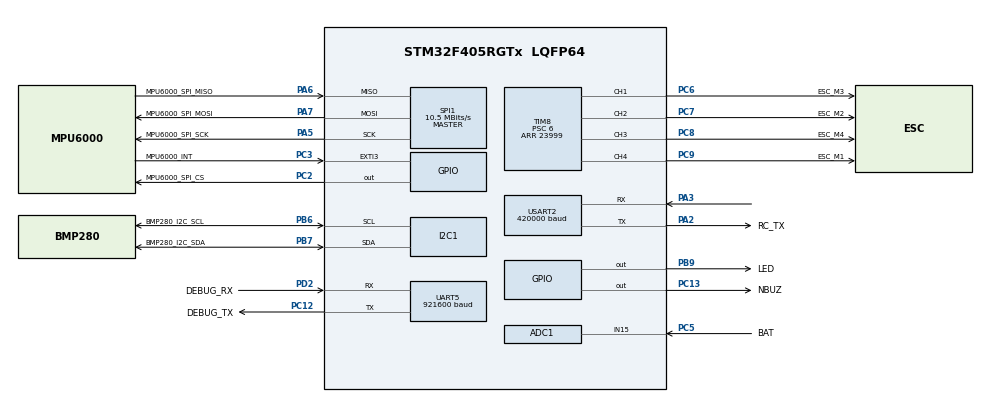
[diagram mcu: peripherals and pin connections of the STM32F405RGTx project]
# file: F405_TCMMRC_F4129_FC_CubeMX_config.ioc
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ADC1.Channel-0\#ChannelRegularConversion=ADC_CHANNEL_15
ADC1.NbrOfConversionFlag=1
ADC1.Rank-0\#ChannelRegularConversion=1
ADC1.SamplingTime-0\#ChannelRegularConversion=ADC_SAMPLETIME_3CYCLES
ADC1.master=1
Dma.Request0=SPI1_RX
Dma.Request1=SPI1_TX
Dma.Request2=USART2_RX
Dma.SPI1_RX.0.Direction=DMA_PERIPH_TO_MEMORY
Dma.SPI1_RX.0.FIFOMode=DMA_FIFOMODE_DISABLE
Dma.SPI1_RX.0.Instance=DMA2_Stream0
Dma.SPI1_RX.0.MemDataAlignment=DMA_MDATAALIGN_BYTE
Dma.SPI1_RX.0.MemInc=DMA_MINC_ENABLE
Dma.SPI1_RX.0.Mode=DMA_NORMAL
Dma.SPI1_RX.0.PeriphDataAlignment=DMA_PDATAALIGN_BYTE
Dma.SPI1_RX.0.PeriphInc=DMA_PINC_DISABLE
Dma.SPI1_RX.0.Priority=DMA_PRIORITY_VERY_HIGH
Dma.SPI1_TX.1.Direction=DMA_MEMORY_TO_PERIPH
Dma.SPI1_TX.1.FIFOMode=DMA_FIFOMODE_DISABLE
Dma.SPI1_TX.1.Instance=DMA2_Stream3
Dma.SPI1_TX.1.MemDataAlignment=DMA_MDATAALIGN_BYTE
Dma.SPI1_TX.1.MemInc=DMA_MINC_ENABLE
Dma.SPI1_TX.1.Mode=DMA_NORMAL
Dma.SPI1_TX.1.PeriphDataAlignment=DMA_PDATAALIGN_BYTE
Dma.SPI1_TX.1.PeriphInc=DMA_PINC_DISABLE
Dma.SPI1_TX.1.Priority=DMA_PRIORITY_VERY_HIGH
Dma.USART2_RX.2.Direction=DMA_PERIPH_TO_MEMORY
Dma.USART2_RX.2.FIFOMode=DMA_FIFOMODE_DISABLE
Dma.USART2_RX.2.Instance=DMA1_Stream5
Dma.USART2_RX.2.MemDataAlignment=DMA_MDATAALIGN_BYTE
Dma.USART2_RX.2.MemInc=DMA_MINC_ENABLE
Dma.USART2_RX.2.Mode=DMA_CIRCULAR
Dma.USART2_RX.2.PeriphDataAlignment=DMA_PDATAALIGN_BYTE
Dma.USART2_RX.2.PeriphInc=DMA_PINC_DISABLE
Dma.USART2_RX.2.Priority=DMA_PRIORITY_HIGH
Mcu.Family=STM32F4
Mcu.Name=STM32F405RGTx
Mcu.Package=LQFP64
NVIC.DMA1_Stream5_IRQn=true\:0\:0\:false\:false\:true\:false\:true\:true
NVIC.DMA2_Stream0_IRQn=true\:2\:0\:true\:false\:true\:false\:true\:true
NVIC.DMA2_Stream3_IRQn=true\:3\:0\:true\:false\:true\:false\:true\:true
NVIC.EXTI3_IRQn=true\:2\:0\:true\:false\:true\:true\:true\:false
NVIC.PriorityGroup=NVIC_PRIORITYGROUP_4
NVIC.USART2_IRQn=true\:0\:0\:false\:false\:true\:true\:true\:true
PA2.GPIO_Label=RC_TX
PA2.Mode=Asynchronous
PA2.Signal=USART2_TX
PA3.Mode=Asynchronous
PA3.Signal=USART2_RX
PA5.GPIO_Label=MPU6000_SPI_SCK
PA5.Mode=Full_Duplex_Master
PA5.Signal=SPI1_SCK
PA6.GPIO_Label=MPU6000_SPI_MISO
PA6.GPIO_PuPd=GPIO_PULLDOWN
PA6.Mode=Full_Duplex_Master
PA6.Signal=SPI1_MISO
PA7.GPIO_Label=MPU6000_SPI_MOSI
PA7.Mode=Full_Duplex_Master
PA7.Signal=SPI1_MOSI
PB6.GPIO_Label=BMP280_I2C_SCL
PB6.Mode=I2C
PB6.Signal=I2C1_SCL
PB7.GPIO_Label=BMP280_I2C_SDA
PB7.Mode=I2C
PB7.Signal=I2C1_SDA
PB9.GPIO_Label=LED
PB9.PinState=GPIO_PIN_SET
PB9.Signal=GPIO_Output
PC12.GPIO_Label=DEBUG_TX
PC12.Mode=Asynchronous
PC12.Signal=UART5_TX
PC13-ANTI_TAMP.GPIO_Label=NBUZ
PC13-ANTI_TAMP.Signal=GPIO_Output
PC2.GPIO_Label=MPU6000_SPI_CS
PC2.GPIO_Speed=GPIO_SPEED_FREQ_VERY_HIGH
PC2.PinState=GPIO_PIN_SET
PC2.Signal=GPIO_Output
PC3.GPIO_Label=MPU6000_INT
PC3.GPIO_PuPd=GPIO_PULLDOWN
PC3.Signal=GPXTI3
PC5.GPIO_Label=BAT
PC5.Signal=ADCx_IN15
PC6.GPIO_Label=ESC_M3
PC6.Signal=S_TIM8_CH1
PC7.GPIO_Label=ESC_M2
PC7.Signal=S_TIM8_CH2
PC8.GPIO_Label=ESC_M4
PC8.Signal=S_TIM8_CH3
PC9.GPIO_Label=ESC_M1
PC9.Signal=S_TIM8_CH4
PD2.GPIO_Label=DEBUG_RX
PD2.Mode=Asynchronous
PD2.Signal=UART5_RX
PH0-OSC_IN.Mode=HSE-External-Oscillator
PH0-OSC_IN.Signal=RCC_OSC_IN
PH1-OSC_OUT.Mode=HSE-External-Oscillator
PH1-OSC_OUT.Signal=RCC_OSC_OUT
ProjectManager.HeapSize=0x200
ProjectManager.StackSize=0x400
ProjectManager.TargetToolchain=CMake
RCC.48MHZClocksFreq_Value=84000000
RCC.AHBFreq_Value=168000000
RCC.APB1CLKDivider=RCC_HCLK_DIV4
RCC.APB1Freq_Value=42000000
RCC.APB1TimFreq_Value=84000000
RCC.APB2CLKDivider=RCC_HCLK_DIV2
RCC.APB2Freq_Value=84000000
RCC.APB2TimFreq_Value=168000000
RCC.CortexFreq_Value=168000000
RCC.HCLKFreq_Value=168000000
RCC.HSE_VALUE=8000000
RCC.HSI_VALUE=16000000
RCC.LSE_VALUE=32768
RCC.PLLM=4
RCC.PLLN=168
RCC.PLLSourceVirtual=RCC_PLLSOURCE_HSE
RCC.SYSCLKFreq_VALUE=168000000
RCC.SYSCLKSource=RCC_SYSCLKSOURCE_PLLCLK
RCC.VCOOutputFreq_Value=336000000
SH.ADCx_IN15.0=ADC1_IN15,IN15
SH.S_TIM8_CH1.0=TIM8_CH1,PWM Generation1 CH1
SH.S_TIM8_CH2.0=TIM8_CH2,PWM Generation2 CH2
SH.S_TIM8_CH3.0=TIM8_CH3,PWM Generation3 CH3
SH.S_TIM8_CH4.0=TIM8_CH4,PWM Generation4 CH4
SPI1.BaudRatePrescaler=SPI_BAUDRATEPRESCALER_8
SPI1.CLKPhase=SPI_PHASE_2EDGE
SPI1.CLKPolarity=SPI_POLARITY_HIGH
SPI1.CalculateBaudRate=10.5 MBits/s
SPI1.Direction=SPI_DIRECTION_2LINES
SPI1.Mode=SPI_MODE_MASTER
SPI1.VirtualType=VM_MASTER
TIM8.Channel-PWM\ Generation1\ CH1=TIM_CHANNEL_1
TIM8.Channel-PWM\ Generation2\ CH2=TIM_CHANNEL_2
TIM8.Channel-PWM\ Generation3\ CH3=TIM_CHANNEL_3
TIM8.Channel-PWM\ Generation4\ CH4=TIM_CHANNEL_4
TIM8.Period=23999
TIM8.Prescaler=6
TIM8.Pulse-PWM\ Generation1\ CH1=3000
TIM8.Pulse-PWM\ Generation2\ CH2=3000
TIM8.Pulse-PWM\ Generation3\ CH3=3000
TIM8.Pulse-PWM\ Generation4\ CH4=3000
UART5.BaudRate=921600
UART5.VirtualMode=Asynchronous
USART2.BaudRate=420000
USART2.VirtualMode=VM_ASYNC
board=custom

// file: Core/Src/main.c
/* USER CODE BEGIN Header */
/**
  ******************************************************************************
  * @file           : main.c
  * @brief          : Main program body
  ******************************************************************************
  * @attention
  *
  * Copyright (c) 2026 STMicroelectronics.
  * All rights reserved.
  *
  * This software is licensed under terms that can be found in the LICENSE file
  * in the root directory of this software component.
  * If no LICENSE file comes with this software, it is provided AS-IS.
  *
  ******************************************************************************
  */
/* USER CODE END Header */
#include "main.h"
#include "adc.h"
#include "dma.h"
#include "i2c.h"
#include "spi.h"
#include "tim.h"
#include "usart.h"
#include "gpio.h"

/* USER CODE BEGIN Includes */
#include "global.h"
#include "led_driver.h"
#include "esc_driver.h"
#include "remote_driver.h"
#include "security.h"
#include "debug.h"
#include "mpu6000_driver.h"

/* USER CODE END Includes */

void SystemClock_Config(void);

int main(void)
{

  /* USER CODE BEGIN 1 */
  debug_init =1;
  debug_rc = 1;
  debug_imu = 1;
  debug_warn = 1;
  /* USER CODE END 1 */

  /* MCU Configuration--------------------------------------------------------*/

  /* Reset of all peripherals, Initializes the Flash interface and the Systick. */
  LL_APB2_GRP1_EnableClock(LL_APB2_GRP1_PERIPH_SYSCFG);
  LL_APB1_GRP1_EnableClock(LL_APB1_GRP1_PERIPH_PWR);

  /* System interrupt init*/
  NVIC_SetPriorityGrouping(NVIC_PRIORITYGROUP_4);

  /* SysTick_IRQn interrupt configuration */
  NVIC_SetPriority(SysTick_IRQn, NVIC_EncodePriority(NVIC_GetPriorityGrouping(),15, 0));

  /* Configure the system clock */
  SystemClock_Config();

  /* Initialize all configured peripherals */
  MX_GPIO_Init();
  MX_DMA_Init();
  MX_ADC1_Init();
  MX_I2C1_Init();
  MX_SPI1_Init();
  MX_TIM8_Init();
  MX_UART5_Init();
  MX_USART2_UART_Init();
  /* USER CODE BEGIN 2 */
  LED_On();
  //ESC_Init();
  //ESC_Test();
  //MPU6000_Init();
  //Remote_Init();

  /* USER CODE END 2 */

  /* Infinite loop */
  while (1)
  {

  }
}

void SystemClock_Config(void)
{
  LL_FLASH_SetLatency(LL_FLASH_LATENCY_5);
  while(LL_FLASH_GetLatency()!= LL_FLASH_LATENCY_5)
  {
  }
  LL_PWR_SetRegulVoltageScaling(LL_PWR_REGU_VOLTAGE_SCALE1);
  LL_RCC_HSE_Enable();

   /* Wait till HSE is ready */
  while(LL_RCC_HSE_IsReady() != 1)
  {

  }
  LL_RCC_PLL_ConfigDomain_SYS(LL_RCC_PLLSOURCE_HSE, LL_RCC_PLLM_DIV_4, 168, LL_RCC_PLLP_DIV_2);
  LL_RCC_PLL_Enable();

   /* Wait till PLL is ready */
  while(LL_RCC_PLL_IsReady() != 1)
  {

  }
  while (LL_PWR_IsActiveFlag_VOS() == 0)
  {
  }
  LL_RCC_SetAHBPrescaler(LL_RCC_SYSCLK_DIV_1);
  LL_RCC_SetAPB1Prescaler(LL_RCC_APB1_DIV_4);
  LL_RCC_SetAPB2Prescaler(LL_RCC_APB2_DIV_2);
  LL_RCC_SetSysClkSource(LL_RCC_SYS_CLKSOURCE_PLL);

   /* Wait till System clock is ready */
  while(LL_RCC_GetSysClkSource() != LL_RCC_SYS_CLKSOURCE_STATUS_PLL)
  {

  }
  LL_Init1msTick(168000000);
  LL_SetSystemCoreClock(168000000);
}

void Error_Handler(void)
{
  __disable_irq();
  while (1)
  {
  }
}
